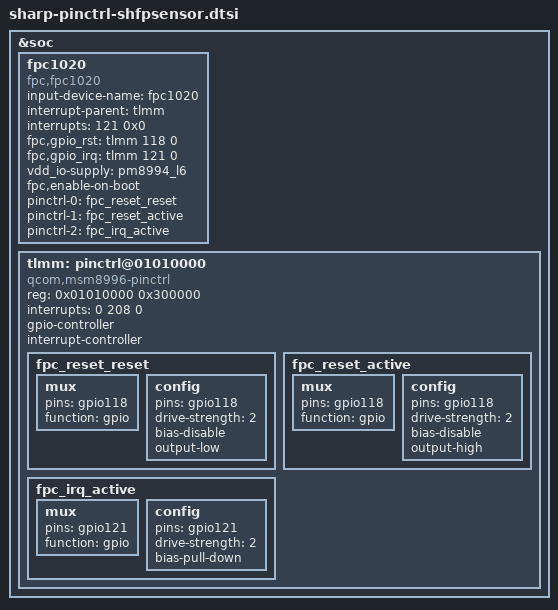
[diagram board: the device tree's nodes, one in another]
/* Copyright (c) 2015, The Linux Foundation. All rights reserved.
 *
 * This program is free software; you can redistribute it and/or modify
 * it under the terms of the GNU General Public License version 2 and
 * only version 2 as published by the Free Software Foundation.
 *
 * This program is distributed in the hope that it will be useful,
 * but WITHOUT ANY WARRANTY; without even the implied warranty of
 * MERCHANTABILITY or FITNESS FOR A PARTICULAR PURPOSE.  See the
 * GNU General Public License for more details.
 */

&soc {
	fpc1020 {
		status = "ok";
		compatible = "fpc,fpc1020";
		input-device-name = "fpc1020";
		interrupt-parent = <&tlmm>;
		interrupts = <121 0x0>;
		fpc,gpio_rst    = <&tlmm 118 0>;
		fpc,gpio_irq    = <&tlmm 121 0>;
		vdd_io-supply   = <&pm8994_l6>;
		fpc,enable-on-boot;

		pinctrl-names = "fpc1020_reset_reset",
				"fpc1020_reset_active",
				"fpc1020_irq_active";

		pinctrl-0 = <&fpc_reset_reset>;
		pinctrl-1 = <&fpc_reset_active>;
		pinctrl-2 = <&fpc_irq_active>;
	};

	tlmm: pinctrl@01010000 {
		compatible = "qcom,msm8996-pinctrl";
		reg = <0x01010000 0x300000>;
		interrupts = <0 208 0>;
		gpio-controller;
		#gpio-cells = <2>;
		interrupt-controller;
		#interrupt-cells = <2>;

		/*****************************************/
		/*  pinctrl customize setting            */
		/*****************************************/

		fpc_reset_reset: fpc_reset_reset {
			mux {
				pins = "gpio118";
				function = "gpio";
			};
			config {
				pins = "gpio118";
				drive-strength = <2>;
				bias-disable;
				output-low;
			};
		};
		fpc_reset_active: fpc_reset_active {
			mux {
				pins = "gpio118";
				function = "gpio";
			};
			config {
				pins = "gpio118";
				drive-strength = <2>;
				bias-disable;
				output-high;
			};
		};

		fpc_irq_active: fpc_irq_active {
			mux {
				pins = "gpio121";
				function = "gpio";
			};
			config {
				pins = "gpio121";
				drive-strength = <2>;
//				bias-disable;
				bias-pull-down;
			};
		};

	};
};

